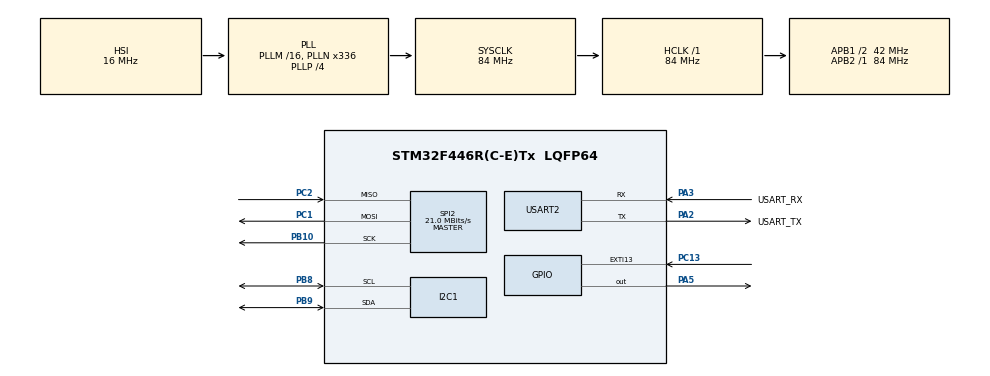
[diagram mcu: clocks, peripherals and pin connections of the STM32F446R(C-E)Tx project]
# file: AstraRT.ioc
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Mcu.Family=STM32F4
Mcu.Name=STM32F446R(C-E)Tx
Mcu.Package=LQFP64
NUCLEO-F446RE.BUTTON=1
NUCLEO-F446RE.LD1=true
NVIC.EXTI15_10_IRQn=true\:0\:0\:false\:false\:true\:false\:true\:true
NVIC.PriorityGroup=NVIC_PRIORITYGROUP_0
PA13.GPIO_Label=TMS
PA13.Signal=SYS_JTMS-SWDIO
PA14.GPIO_Label=TCK
PA14.Signal=SYS_JTCK-SWCLK
PA2.GPIO_Label=USART_TX
PA2.Mode=Asynchronous
PA2.Signal=USART2_TX
PA3.GPIO_Label=USART_RX
PA3.Mode=Asynchronous
PA3.Signal=USART2_RX
PA5.Signal=GPIO_Output
PB10.Mode=Full_Duplex_Master
PB10.Signal=SPI2_SCK
PB3.GPIO_Label=SWO
PB3.Signal=SYS_JTDO-SWO
PB8.Mode=I2C
PB8.Signal=I2C1_SCL
PB9.Mode=I2C
PB9.Signal=I2C1_SDA
PC1.Mode=Full_Duplex_Master
PC1.Signal=SPI2_MOSI
PC13.Signal=GPXTI13
PC14-OSC32_IN.Signal=RCC_OSC32_IN
PC15-OSC32_OUT.Signal=RCC_OSC32_OUT
PC2.Mode=Full_Duplex_Master
PC2.Signal=SPI2_MISO
PH0-OSC_IN.Signal=RCC_OSC_IN
PH1-OSC_OUT.Signal=RCC_OSC_OUT
ProjectManager.HeapSize=0x200
ProjectManager.StackSize=0x400
ProjectManager.TargetToolchain=STM32CubeIDE
RCC.AHBFreq_Value=84000000
RCC.APB1CLKDivider=RCC_HCLK_DIV2
RCC.APB1Freq_Value=42000000
RCC.APB1TimFreq_Value=84000000
RCC.APB2Freq_Value=84000000
RCC.APB2TimFreq_Value=84000000
RCC.CortexFreq_Value=84000000
RCC.FLatency-AdvancedSettings=FLASH_LATENCY_2
RCC.HCLKFreq_Value=84000000
RCC.HSE_VALUE=8000000
RCC.HSI_VALUE=16000000
RCC.LSE_VALUE=32768
RCC.PLLN=336
RCC.PLLP=RCC_PLLP_DIV4
RCC.SYSCLKFreq_VALUE=84000000
RCC.SYSCLKSource=RCC_SYSCLKSOURCE_PLLCLK
RCC.USBFreq_Value=168000000
RCC.VCOOutputFreq_Value=336000000
SPI2.CalculateBaudRate=21.0 MBits/s
SPI2.Direction=SPI_DIRECTION_2LINES
SPI2.Mode=SPI_MODE_MASTER
SPI2.VirtualType=VM_MASTER
USART2.VirtualMode=VM_ASYNC
VP_NUCLEO-F446RE_VS_BSP_COMMON.Mode=COMMON
board=NUCLEO-F446RE

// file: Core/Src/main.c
/* USER CODE BEGIN Header */
/**
  ******************************************************************************
  * @file           : main.c
  * @brief          : Main program body
  ******************************************************************************
  * @attention
  *
  * Copyright (c) 2026 STMicroelectronics.
  * All rights reserved.
  *
  * This software is licensed under terms that can be found in the LICENSE file
  * in the root directory of this software component.
  * If no LICENSE file comes with this software, it is provided AS-IS.
  *
  ******************************************************************************
  */
/* USER CODE END Header */
#include "gpio.h"
#include "i2c.h"
#include "main.h"
#include "spi.h"
#include "usart.h"

/* USER CODE BEGIN Includes */
#include "astra_gpio.h"
#include "astra_i2c.h"
#include "astra_uart.h"
#include "bmi160.h"
#include "Runtime/runtime.h"
#include "Runtime/Scheduler/scheduler.h"
#include <stdio.h>
#include <string.h>
/* USER CODE END Includes */

void SystemClock_Config(void);

int main(void)
{

  /* MCU Configuration--------------------------------------------------------*/

  /* Reset of all peripherals, Initializes the Flash interface and the Systick. */
  HAL_Init();

  /* Configure the system clock */
  SystemClock_Config();

  /* Initialize all configured peripherals */
  /* Initialize hardware peripherals */
  MX_GPIO_Init();
  MX_USART2_UART_Init();
  MX_I2C1_Init();
  MX_SPI2_Init();

  /* Initialize AstraRT runtime */
  runtime_init();
  scheduler_timer_init();

  /* Initialize platform drivers */
  BMI160_Init();

  /* Initialize leds */
  BSP_LED_Init(LED2);

  /* Initialize USER push-button, will be used to trigger an interrupt each time it's pressed.*/
  BSP_PB_Init(BUTTON_USER, BUTTON_MODE_EXTI);

  /* Infinite loop */
  /* USER CODE BEGIN WHILE */
  while (1)
  {
	    scheduler_run();

    /* USER CODE END WHILE */

  }
}

void SystemClock_Config(void)
{
  RCC_OscInitTypeDef RCC_OscInitStruct = {0};
  RCC_ClkInitTypeDef RCC_ClkInitStruct = {0};

  /** Configure the main internal regulator output voltage
  */
  __HAL_RCC_PWR_CLK_ENABLE();
  __HAL_PWR_VOLTAGESCALING_CONFIG(PWR_REGULATOR_VOLTAGE_SCALE3);

  /** Initializes the RCC Oscillators according to the specified parameters
  * in the RCC_OscInitTypeDef structure.
  */
  RCC_OscInitStruct.OscillatorType = RCC_OSCILLATORTYPE_HSI;
  RCC_OscInitStruct.HSIState = RCC_HSI_ON;
  RCC_OscInitStruct.HSICalibrationValue = RCC_HSICALIBRATION_DEFAULT;
  RCC_OscInitStruct.PLL.PLLState = RCC_PLL_ON;
  RCC_OscInitStruct.PLL.PLLSource = RCC_PLLSOURCE_HSI;
  RCC_OscInitStruct.PLL.PLLM = 16;
  RCC_OscInitStruct.PLL.PLLN = 336;
  RCC_OscInitStruct.PLL.PLLP = RCC_PLLP_DIV4;
  RCC_OscInitStruct.PLL.PLLQ = 2;
  RCC_OscInitStruct.PLL.PLLR = 2;
  if (HAL_RCC_OscConfig(&RCC_OscInitStruct) != HAL_OK)
  {
    Error_Handler();
  }

  /** Initializes the CPU, AHB and APB buses clocks
  */
  RCC_ClkInitStruct.ClockType = RCC_CLOCKTYPE_HCLK|RCC_CLOCKTYPE_SYSCLK
                              |RCC_CLOCKTYPE_PCLK1|RCC_CLOCKTYPE_PCLK2;
  RCC_ClkInitStruct.SYSCLKSource = RCC_SYSCLKSOURCE_PLLCLK;
  RCC_ClkInitStruct.AHBCLKDivider = RCC_SYSCLK_DIV1;
  RCC_ClkInitStruct.APB1CLKDivider = RCC_HCLK_DIV2;
  RCC_ClkInitStruct.APB2CLKDivider = RCC_HCLK_DIV1;

  if (HAL_RCC_ClockConfig(&RCC_ClkInitStruct, FLASH_LATENCY_2) != HAL_OK)
  {
    Error_Handler();
  }
}

void Error_Handler(void)
{
  __disable_irq();
  while (1)
  {
  }
}
